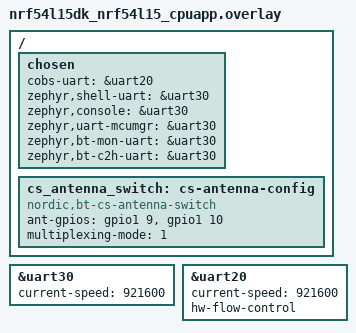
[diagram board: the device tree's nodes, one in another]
/*
 * Copyright (c) 2025 Nordic Semiconductor ASA
 *
 * SPDX-License-Identifier: LicenseRef-Nordic-5-Clause
 */

/ {
    chosen {
        cobs-uart = &uart20;
        zephyr,shell-uart = &uart30;
        zephyr,console = &uart30;
        zephyr,uart-mcumgr = &uart30;
        zephyr,bt-mon-uart = &uart30;
        zephyr,bt-c2h-uart = &uart30;

    };
};

&uart30 {
    status = "okay";
    current-speed = <921600>;
};

&uart20 {
    status = "okay";
    current-speed = <921600>;
    hw-flow-control;
};

/ {
    cs_antenna_switch: cs-antenna-config {
        status = "okay";
        compatible = "nordic,bt-cs-antenna-switch";
        ant-gpios = <&gpio1 9 GPIO_ACTIVE_HIGH>,
                    <&gpio1 10 GPIO_ACTIVE_HIGH>;
        multiplexing-mode = <1>;
    };
};
